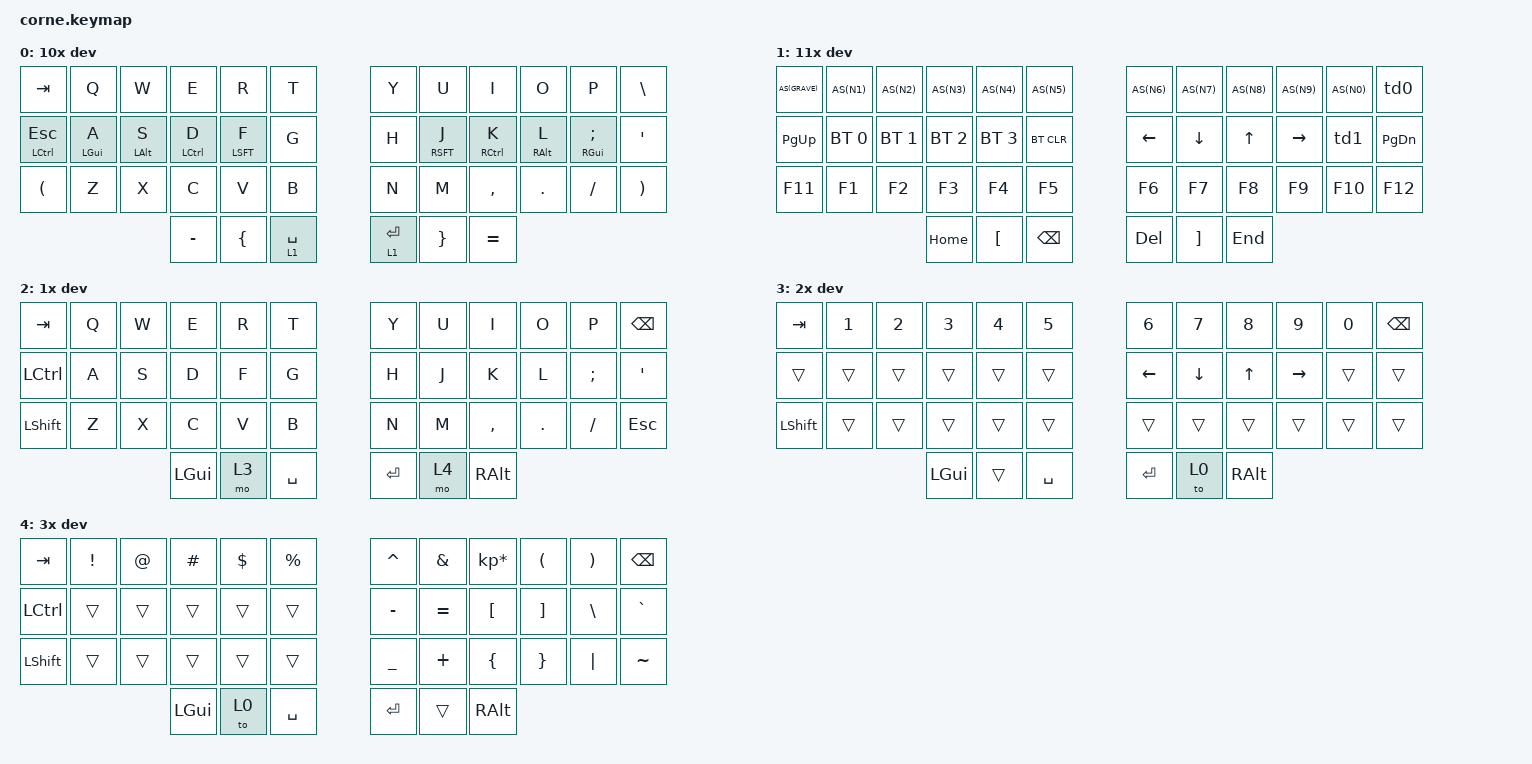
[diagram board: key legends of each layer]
/*
 * Copyright (c) 2020 The ZMK Contributors
 *
 * SPDX-License-Identifier: MIT
 */

#include <behaviors.dtsi>
#include <dt-bindings/zmk/keys.h>
#include <dt-bindings/zmk/bt.h>

#define AS(keycode) &as LS(keycode) keycode     // Autoshift Macro

/ {
        behaviors {
                as: auto_shift {
                        compatible = "zmk,behavior-hold-tap";
                        #binding-cells = <2>;
                        tapping_term_ms = <200>;
                        quick_tap_ms = <0>;
                        flavor = "tap-preferred";
                        bindings = <&kp>, <&kp>;
                };
                td0: tap_dance_0 {
                        compatible = "zmk,behavior-tap-dance";
                        #binding-cells = <0>;
                        tapping-term-ms = <500>;
                        bindings = <&kp C_MUTE>, <&kp PSCRN>, <&kp C_AL_CALC>;
                };
                td1: tap_dance_1 {
                        compatible = "zmk,behavior-tap-dance";
                        #binding-cells = <0>;
                        tapping-term-ms = <500>;
                        bindings = <&kp K_CANCEL>, <&kp K_CANCEL>, <&to 2>;
                };
        };

        keymap {
                compatible = "zmk,keymap";

                default_layer {
// -----------------------------------------------------------------------------------------
// |  TAB |  Q  |  W  |  E  |  R  |  T  |   |  Y  |  U   |  I  |  O  |  P  |  \   |
// |  ESC |  A  |  S  |  D  |  F  |  G  |   |  H  |  J   |  K  |  L  |  ;  |  '   |
// |   (  |  Z  |  X  |  C  |  V  |  B  |   |  N  |  M   |  ,  |  .  |  /  |  )   |
//                    |  -  |  {  | SPC |   | ENT |  }   |  =  |
                        display-name = "10x dev";
                        bindings = <
        &kp TAB         &kp Q           &kp W           &kp E           &kp R           &kp T           &kp Y           &kp U           &kp I           &kp O           &kp P           &kp BSLH
        &mt LCTL ESC    &mt LGUI A      &mt LALT S      &mt LCTL D      &mt LSFT F      &kp G           &kp H           &mt RSFT J      &mt RCTL K      &mt RALT L      &mt RGUI SEMI   &kp SQT
        &kp LPAR        &kp Z           &kp X           &kp C           &kp V           &kp B           &kp N           &kp M           &kp COMMA       &kp DOT         &kp FSLH        &kp RPAR
                                &kp MINUS       &kp LBRC        &lt 1 SPACE     &lt 1 RET       &kp RBRC        &kp EQUAL
                        >;
                };
                magic_layer {
// -----------------------------------------------------------------------------------------
// |  `   |  1  |  2  |  3  |  4  |  5  |   |  6  |  7   |  8  |  9  |  0  | PSCRN|
// | PG_UP| BT1 | BT2 | BT3 | BT4 |BTCLR|   | LFT | DWN  |  UP | RGT |     | PG_DN|
// | F11  |  F1 | F2  |  F3 |  F4 |  F5 |   |  F6 |  F7  |  F8 |  F9 | F10 | F12  |
//                    | HOME|  [  |BKSP |   | DEL |  ]   | END |
                        display-name = "11x dev";
                        bindings = <
        AS(GRAVE)       AS(N1)          AS(N2)          AS(N3)          AS(N4)          AS(N5)          AS(N6)          AS(N7)          AS(N8)          AS(N9)          AS(N0)          &td0
        &kp PG_UP       &bt BT_SEL 0    &bt BT_SEL 1    &bt BT_SEL 2    &bt BT_SEL 3    &bt BT_CLR      &kp LEFT        &kp DOWN        &kp UP          &kp RIGHT       &td1            &kp PG_DN
        &kp F11         &kp F1          &kp F2          &kp F3          &kp F4          &kp F5          &kp F6          &kp F7          &kp F8          &kp F9          &kp F10         &kp F12
                                                        &kp HOME        &kp LBKT        &kp BSPC        &kp DEL         &kp RBKT        &kp END
                        >;
                };
                basic_layer {
// -----------------------------------------------------------------------------------------
// |  TAB |  Q  |  W  |  E  |  R  |  T  |   |  Y  |  U   |  I  |  O  |  P  | BKSP |
// | CTRL |  A  |  S  |  D  |  F  |  G  |   |  H  |  J   |  K  |  L  |  ;  |  '   |
// | SHFT |  Z  |  X  |  C  |  V  |  B  |   |  N  |  M   |  ,  |  .  |  /  | ESC  |
//                    | GUI | LWR | SPC |   | ENT | RSE  | ALT |
                        display-name = "1x dev";
                        bindings = <
   &kp TAB   &kp Q &kp W &kp E &kp R &kp T   &kp Y &kp U  &kp I     &kp O   &kp P    &kp BSPC
   &kp LCTRL &kp A &kp S &kp D &kp F &kp G   &kp H &kp J  &kp K     &kp L   &kp SEMI &kp SQT
   &kp LSHFT &kp Z &kp X &kp C &kp V &kp B   &kp N &kp M  &kp COMMA &kp DOT &kp FSLH &kp ESC
                  &kp LGUI &mo 3 &kp SPACE   &kp RET &mo 4 &kp RALT
                        >;
                };
                lower_layer {
// -----------------------------------------------------------------------------------------
// |  TAB |  1  |  2  |  3  |  4  |  5  |   |  6  |  7  |  8  |  9  |  0  | BKSP |
// |      |     |     |     |     |     |   | LFT | DWN |  UP | RGT |     |      |
// | SHFT |     |     |     |     |     |   |     |     |     |     |     |      |
//                    | GUI |     | SPC |   | ENT |     | ALT |
                        display-name = "2x dev";
                        bindings = <
   &kp TAB    &kp N1       &kp N2       &kp N3       &kp N4       &kp N5         &kp N6   &kp N7   &kp N8 &kp N9    &kp N0 &kp BSPC
   &trans     &trans       &trans       &trans       &trans       &trans         &kp LEFT &kp DOWN &kp UP &kp RIGHT &trans &trans
   &kp LSHFT  &trans       &trans       &trans       &trans       &trans         &trans   &trans   &trans &trans    &trans &trans
                          	        &kp LGUI     &trans       &kp SPACE      &kp RET  &to 0    &kp RALT
                        >;
                };

                raise_layer {
// -----------------------------------------------------------------------------------------
// |  TAB |  !  |  @  |  #  |  $  |  %  |   |  ^  |  &  |  *  |  (  |  )  | BKSP |
// | CTRL |     |     |     |     |     |   |  -  |  =  |  [  |  ]  |  \  |  `   |
// | SHFT |     |     |     |     |     |   |  _  |  +  |  {  |  }  | "|" |  ~   |
//                    | GUI |     | SPC |   | ENT |     | ALT |
                        display-name = "3x dev";
                        bindings = <
   &kp  TAB  &kp EXCL &kp AT &kp HASH &kp DLLR &kp PRCNT   &kp CARET &kp AMPS  &kp KP_MULTIPLY &kp LPAR &kp RPAR &kp BSPC
   &kp LCTRL &trans   &trans &trans   &trans   &trans      &kp MINUS &kp EQUAL &kp LBKT        &kp RBKT &kp BSLH &kp GRAVE
   &kp LSHFT &trans   &trans &trans   &trans   &trans      &kp UNDER &kp PLUS  &kp LBRC        &kp RBRC &kp PIPE &kp TILDE
                    	     &kp LGUI &to 0    &kp SPACE   &kp RET   &trans    &kp RALT
                        >;
                };

                extra_1 {
                        status = "reserved";
                };

                extra_2 {
                        status = "reserved";
                };

                extra_3 {
                        status = "reserved";
                };
        };
};
